# COMPUTE_CLUSTER0_CTL_CFG register map
Vendor: Texas Instruments
Registers are 32-bit, read-write, reset 0x0 unless marked. A register's access mark holds for its fields unless they carry their own. Offsets are as the file gives them; [hi:lo] are bit positions; {n}, {i} and the like mark numbered series.

## COMPUTE_CLUSTER0_CTL_CFG (part 2 of 3)
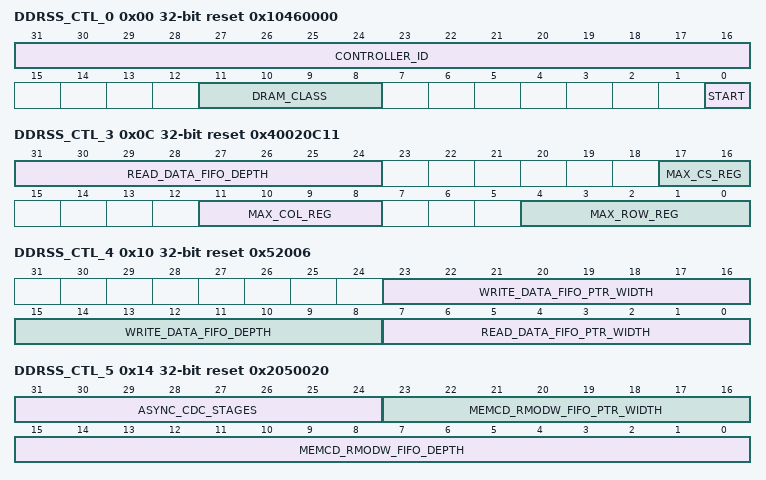
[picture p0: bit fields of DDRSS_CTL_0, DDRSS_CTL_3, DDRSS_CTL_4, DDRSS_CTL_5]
0x00 DDRSS_CTL_0 access per field reset 0x10460000
  [31:16] CONTROLLER_ID ro — Holds the controller product id number.
  [11:8] DRAM_CLASS rw — Defines the class of DRAM memory which is connected to the controller.7h - LPDDR3Bh - LPDDR4All other values reserved
  [0] START rw — Initiate command processing in the controller.
0x04 DDRSS_CTL_1 ro reset 0x67433A40
  [31:0] CONTROLLER_VERSION_0 — Holds the controller version id.
0x08 DDRSS_CTL_2 ro reset 0x22117A20
  [31:0] CONTROLLER_VERSION_1 — Holds the controller version id.
0x0C DDRSS_CTL_3 ro reset 0x40020C11
  [31:24] READ_DATA_FIFO_DEPTH — Reports the depth of the controller core read data queue.
  [17:16] MAX_CS_REG — Holds the maximum number of chip selects available.
  [11:8] MAX_COL_REG — Holds the maximum width of column address in DRAMs.
  [4:0] MAX_ROW_REG — Holds the maximum width of memory address bus.
0x10 DDRSS_CTL_4 ro reset 0x52006
  [23:16] WRITE_DATA_FIFO_PTR_WIDTH — Reports the width of the controller core write data latency queue pointer.
  [15:8] WRITE_DATA_FIFO_DEPTH — Reports the depth of the controller core write data latency queue.
  [7:0] READ_DATA_FIFO_PTR_WIDTH — Reports the width of the controller core read data queue pointer.
0x14 DDRSS_CTL_5 ro reset 0x2050020
  [31:24] ASYNC_CDC_STAGES — Reports the number of synchronizer delays specified for the asynchronous boundary crossings.
  [23:16] MEMCD_RMODW_FIFO_PTR_WIDTH — Reports the width of the controller core read/modify/write FIFO pointer.
  [15:0] MEMCD_RMODW_FIFO_DEPTH — Reports the depth of the controller core read/modify/write FIFO.
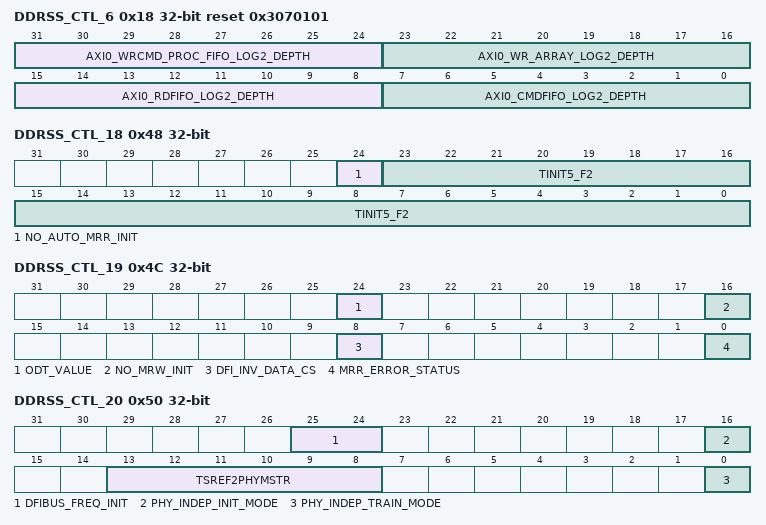
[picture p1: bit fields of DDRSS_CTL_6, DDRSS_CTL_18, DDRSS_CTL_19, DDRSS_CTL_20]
0x18 DDRSS_CTL_6 ro reset 0x3070101
  [31:24] AXI0_WRCMD_PROC_FIFO_LOG2_DEPTH — Reports the depth of the AXI port 0 write command processing FIFO.
  [23:16] AXI0_WR_ARRAY_LOG2_DEPTH — Reports the depth of the AXI port 0 write data array.
  [15:8] AXI0_RDFIFO_LOG2_DEPTH — Reports the depth of the AXI port 0 read data FIFO.
  [7:0] AXI0_CMDFIFO_LOG2_DEPTH — Reports the depth of the AXI port 0 command FIFO.
0x1C DDRSS_CTL_7
  [23:0] TINIT_F0 — DRAM TINIT value for frequency copy 0 in cycles.
{0x0+4i} DDRSS_CTL_{i} (i=8..10)
  [23:0] TINIT{i-5}_F0 — DRAM TINIT{i-5} value for frequency copy 0 in cycles.
0x2C DDRSS_CTL_11
  [23:0] TINIT_F1 — DRAM TINIT value for frequency copy 1 in cycles.
{0x0+4i} DDRSS_CTL_{i} (i=12..14)
  [23:0] TINIT{i-9}_F1 — DRAM TINIT{i-9} value for frequency copy 1 in cycles.
0x3C DDRSS_CTL_15
  [23:0] TINIT_F2 — DRAM TINIT value for frequency copy 2 in cycles.
0x40 DDRSS_CTL_16
  [23:0] TINIT3_F2 — DRAM TINIT3 value for frequency copy 2 in cycles.
0x44 DDRSS_CTL_17
  [23:0] TINIT4_F2 — DRAM TINIT4 value for frequency copy 2 in cycles.
0x48 DDRSS_CTL_18
  [24] NO_AUTO_MRR_INIT — Disable MRR commands during initialization.
  [23:0] TINIT5_F2 — DRAM TINIT5 value for frequency copy 2 in cycles.
0x4C DDRSS_CTL_19 access per field
  [24] ODT_VALUE rw — When using LPDDR4, this value will be driven out on the dfi_odt signal.
  [16] NO_MRW_INIT rw — Disable MRW commands during initialization.
  [8] DFI_INV_DATA_CS rw — Forces the inversion of the dfi_rddata_cs_n_X and dfi_wrdata_cs_n_X signals.
  [0] MRR_ERROR_STATUS ro — Indicates that an MRR was issued while in self-refresh.
0x50 DDRSS_CTL_20
  [25:24] DFIBUS_FREQ_INIT — Defines the initial DFI bus frequency.
  [16] PHY_INDEP_INIT_MODE — Enable PHY independent initailization mode commands during initialization.
  [13:8] TSREF2PHYMSTR — Specifies the minimum time after a self-refresh exit command on the DFI bus that the Controller will wait for the PHY to assert the dfi_phymstr_req signal, before completing other commands.
  [0] PHY_INDEP_TRAIN_MODE — Enable PHY independent training mode commands during initialization.
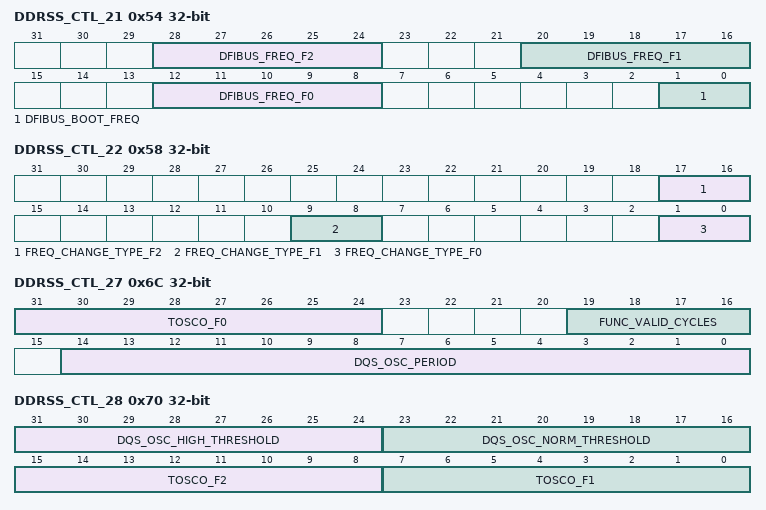
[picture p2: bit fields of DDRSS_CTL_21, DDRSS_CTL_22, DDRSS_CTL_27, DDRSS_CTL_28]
0x54 DDRSS_CTL_21
  [28:24] DFIBUS_FREQ_F2 — Defines the DFI bus frequency for frequency copy 2.
  [20:16] DFIBUS_FREQ_F1 — Defines the DFI bus frequency for frequency copy 1.
  [12:8] DFIBUS_FREQ_F0 — Defines the DFI bus frequency for frequency copy 0.
  [1:0] DFIBUS_BOOT_FREQ — Defines the DFI bus boot frequency.
0x58 DDRSS_CTL_22
  [17:16] FREQ_CHANGE_TYPE_F2 — Defines the encoded frequency driven out on the cntrl_freq_change_req_type signal during a frequency change operation.
  [9:8] FREQ_CHANGE_TYPE_F1 — Defines the encoded frequency driven out on the cntrl_freq_change_req_type signal during a frequency change operation.
  [1:0] FREQ_CHANGE_TYPE_F0 — Defines the encoded frequency driven out on the cntrl_freq_change_req_type signal during a frequency change operation.
0x5C DDRSS_CTL_23
  [31:0] TRST_PWRON — Duration of memory reset during power-on initialization.
0x60 DDRSS_CTL_24
  [31:0] CKE_INACTIVE — Number of cycles after reset before CKE will be active.
0x68 DDRSS_CTL_26
  [16] DQS_OSC_ENABLE — Enable DQS oscillator measurement function in DRAM.
0x6C DDRSS_CTL_27
  [31:24] TOSCO_F0 — Number of cycles for tOSCO timing parameter for frequency copy 0.
  [19:16] FUNC_VALID_CYCLES — Number of cycles to hold dfi_function_valid asserted.
  [14:0] DQS_OSC_PERIOD — Number of cycles to run the oscillator measurement.
0x70 DDRSS_CTL_28
  [31:24] DQS_OSC_HIGH_THRESHOLD — Number of long counts until the high priority request is asserted for DQS Oscillator.
  [23:16] DQS_OSC_NORM_THRESHOLD — Number of long counts until the normal priority request is asserted for DQS Oscillator.
  [15:8] TOSCO_F2 — Number of cycles for tOSCO timing parameter for frequency copy 2.
  [7:0] TOSCO_F1 — Number of cycles for tOSCO timing parameter for frequency copy 1.
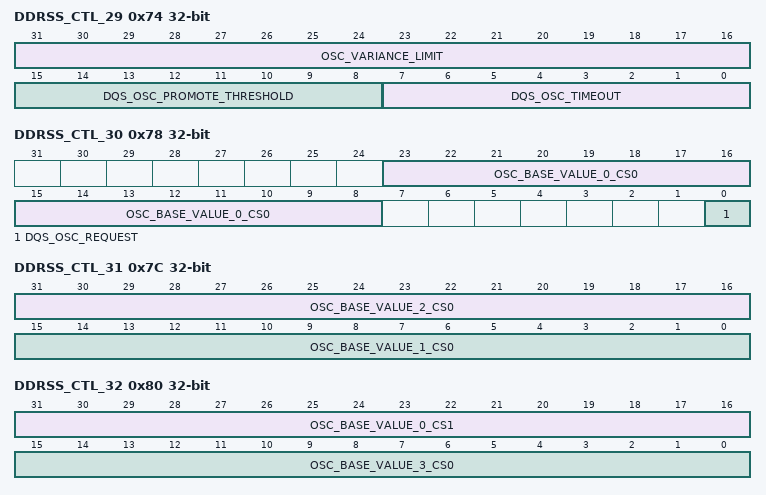
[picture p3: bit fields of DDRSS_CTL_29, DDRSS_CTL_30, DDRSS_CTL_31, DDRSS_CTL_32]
0x74 DDRSS_CTL_29
  [31:16] OSC_VARIANCE_LIMIT — Allowed difference between base value and DQS Oscillator measurement.
  [15:8] DQS_OSC_PROMOTE_THRESHOLD — Number of long counts until a software request for the DQS Oscillator is promoted to high priority.
  [7:0] DQS_OSC_TIMEOUT — Number of long counts until the timeout is asserted for DQS Oscillator.
0x78 DDRSS_CTL_30 access per field
  [23:8] OSC_BASE_VALUE_0_CS0 ro — Base value for device 0 on chip 0.
  [0] DQS_OSC_REQUEST wo — Software request for DQS Oscillator measurement function in DRAM.
0x7C DDRSS_CTL_31 ro
  [31:16] OSC_BASE_VALUE_2_CS0 — Base value for device 2 on chip 0.
  [15:0] OSC_BASE_VALUE_1_CS0 — Base value for device 1 on chip 0.
0x80 DDRSS_CTL_32 ro
  [31:16] OSC_BASE_VALUE_0_CS1 — Base value for device 0 on chip 1.
  [15:0] OSC_BASE_VALUE_3_CS0 — Base value for device 3 on chip 0.
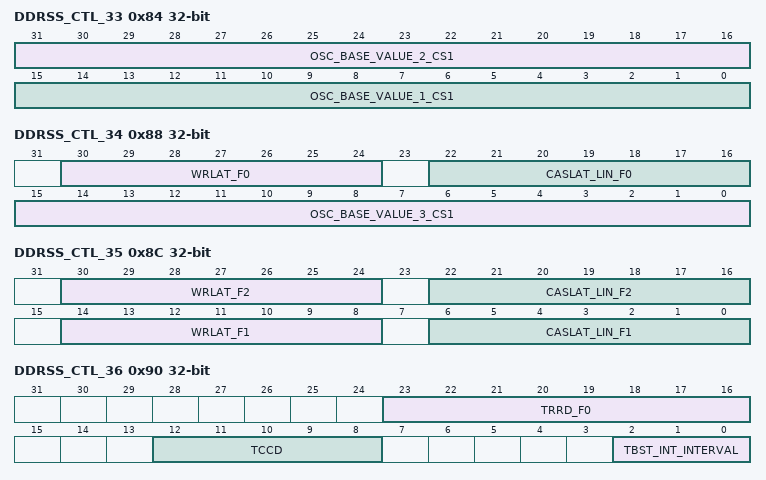
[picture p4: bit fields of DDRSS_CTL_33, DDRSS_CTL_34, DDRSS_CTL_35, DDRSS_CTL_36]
0x84 DDRSS_CTL_33 ro
  [31:16] OSC_BASE_VALUE_2_CS1 — Base value for device 2 on chip 1.
  [15:0] OSC_BASE_VALUE_1_CS1 — Base value for device 1 on chip 1.
0x88 DDRSS_CTL_34 access per field
  [30:24] WRLAT_F0 rw — DRAM WRLAT value for frequency copy 0 in cycles.
  [22:16] CASLAT_LIN_F0 rw — Sets latency from read command send to data receive from/to controller for frequency copy 0.
  [15:0] OSC_BASE_VALUE_3_CS1 ro — Base value for device 3 on chip 1.
0x8C DDRSS_CTL_35
  [30:24] WRLAT_F2 — DRAM WRLAT value for frequency copy 2 in cycles.
  [22:16] CASLAT_LIN_F2 — Sets latency from read command send to data receive from/to controller for frequency copy 2.
  [14:8] WRLAT_F1 — DRAM WRLAT value for frequency copy 1 in cycles.
  [6:0] CASLAT_LIN_F1 — Sets latency from read command send to data receive from/to controller for frequency copy 1.
0x90 DDRSS_CTL_36
  [23:16] TRRD_F0 — DRAM TRRD value for frequency copy 0 in cycles.
  [12:8] TCCD — DRAM CAS-to-CAS value in cycles.
  [2:0] TBST_INT_INTERVAL — DRAM burst interrupt interval value in cycles.
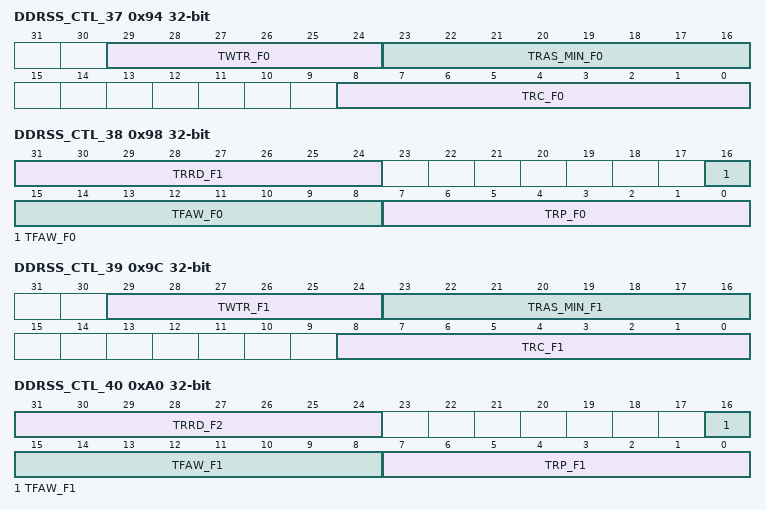
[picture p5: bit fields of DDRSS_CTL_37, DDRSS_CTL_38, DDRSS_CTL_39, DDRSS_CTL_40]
0x94 DDRSS_CTL_37
  [29:24] TWTR_F0 — DRAM TWTR value for frequency copy 0 in cycles.
  [23:16] TRAS_MIN_F0 — DRAM TRAS_MIN value for frequency copy 0 in cycles.
  [8:0] TRC_F0 — DRAM TRC value for frequency copy 0 in cycles.
0x98 DDRSS_CTL_38
  [31:24] TRRD_F1 — DRAM TRRD value for frequency copy 1 in cycles.
  [16:8] TFAW_F0 — DRAM TFAW value for frequency copy 0 in cycles.
  [7:0] TRP_F0 — DRAM TRP value for frequency copy 0 in cycles.
0x9C DDRSS_CTL_39
  [29:24] TWTR_F1 — DRAM TWTR value for frequency copy 1 in cycles.
  [23:16] TRAS_MIN_F1 — DRAM TRAS_MIN value for frequency copy 1 in cycles.
  [8:0] TRC_F1 — DRAM TRC value for frequency copy 1 in cycles.
0xA0 DDRSS_CTL_40
  [31:24] TRRD_F2 — DRAM TRRD value for frequency copy 2 in cycles.
  [16:8] TFAW_F1 — DRAM TFAW value for frequency copy 1 in cycles.
  [7:0] TRP_F1 — DRAM TRP value for frequency copy 1 in cycles.
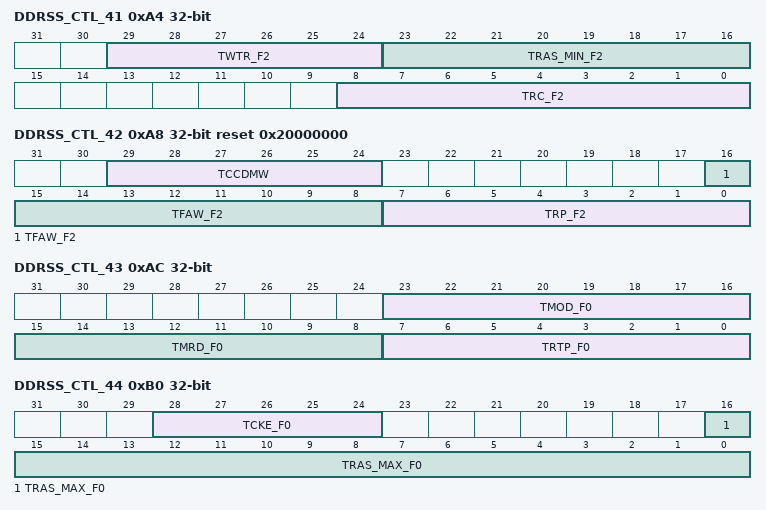
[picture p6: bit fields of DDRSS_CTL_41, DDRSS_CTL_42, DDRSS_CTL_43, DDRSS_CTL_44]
0xA4 DDRSS_CTL_41
  [29:24] TWTR_F2 — DRAM TWTR value for frequency copy 2 in cycles.
  [23:16] TRAS_MIN_F2 — DRAM TRAS_MIN value for frequency copy 2 in cycles.
  [8:0] TRC_F2 — DRAM TRC value for frequency copy 2 in cycles.
0xA8 DDRSS_CTL_42 reset 0x20000000
  [29:24] TCCDMW — DRAM CAS-to-CAS masked write value in cycles.
  [16:8] TFAW_F2 — DRAM TFAW value for frequency copy 2 in cycles.
  [7:0] TRP_F2 — DRAM TRP value for frequency copy 2 in cycles.
0xAC DDRSS_CTL_43
  [23:16] TMOD_F0 — DRAM TMOD value for frequency copy 0 in cycles.
  [15:8] TMRD_F0 — DRAM TMRD value for frequency copy 0 in cycles.
  [7:0] TRTP_F0 — DRAM TRTP value for frequency copy 0 in cycles.
0xB0 DDRSS_CTL_44
  [28:24] TCKE_F0 — Minimum CKE pulse width for frequency copy 0.
  [16:0] TRAS_MAX_F0 — DRAM TRAS_MAX value for frequency copy 0 in cycles.
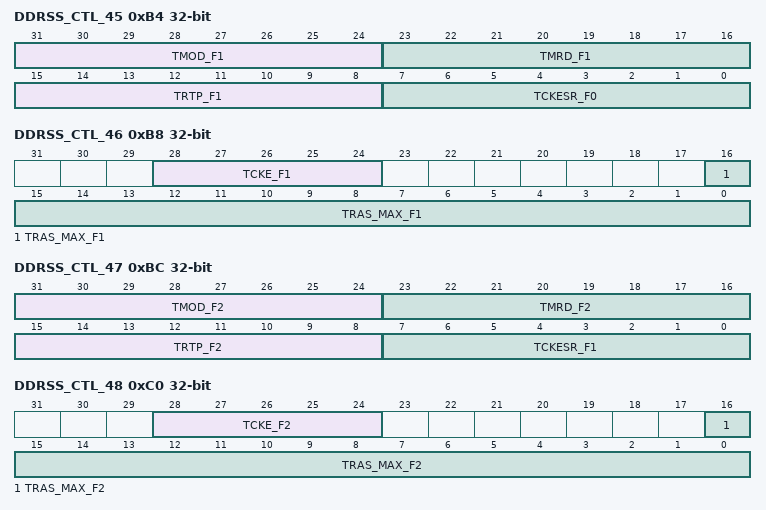
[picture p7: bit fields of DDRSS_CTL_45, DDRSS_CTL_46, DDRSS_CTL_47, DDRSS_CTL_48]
0xB4 DDRSS_CTL_45
  [31:24] TMOD_F1 — DRAM TMOD value for frequency copy 1 in cycles.
  [23:16] TMRD_F1 — DRAM TMRD value for frequency copy 1 in cycles.
  [15:8] TRTP_F1 — DRAM TRTP value for frequency copy 1 in cycles.
  [7:0] TCKESR_F0 — Minimum CKE low pulse width during a self-refresh for frequency copy 0.
0xB8 DDRSS_CTL_46
  [28:24] TCKE_F1 — Minimum CKE pulse width for frequency copy 1.
  [16:0] TRAS_MAX_F1 — DRAM TRAS_MAX value for frequency copy 1 in cycles.
0xBC DDRSS_CTL_47
  [31:24] TMOD_F2 — DRAM TMOD value for frequency copy 2 in cycles.
  [23:16] TMRD_F2 — DRAM TMRD value for frequency copy 2 in cycles.
  [15:8] TRTP_F2 — DRAM TRTP value for frequency copy 2 in cycles.
  [7:0] TCKESR_F1 — Minimum CKE low pulse width during a self-refresh for frequency copy 1.
0xC0 DDRSS_CTL_48
  [28:24] TCKE_F2 — Minimum CKE pulse width for frequency copy 2.
  [16:0] TRAS_MAX_F2 — DRAM TRAS_MAX value for frequency copy 2 in cycles.
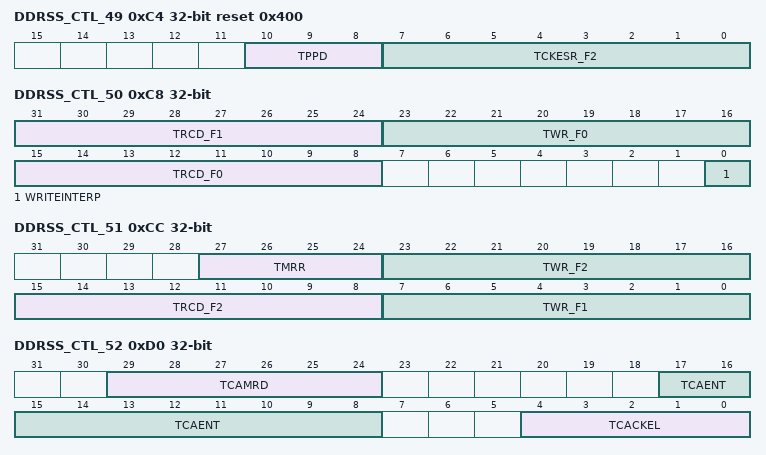
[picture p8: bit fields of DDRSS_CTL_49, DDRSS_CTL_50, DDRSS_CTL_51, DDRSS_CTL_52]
0xC4 DDRSS_CTL_49 reset 0x400
  [10:8] TPPD — DRAM TPPD value in cycles.
  [7:0] TCKESR_F2 — Minimum CKE low pulse width during a self-refresh for frequency copy 2.
0xC8 DDRSS_CTL_50
  [31:24] TRCD_F1 — DRAM TRCD value for frequency copy 1 in cycles.
  [23:16] TWR_F0 — DRAM TWR value for frequency copy 0 in cycles.
  [15:8] TRCD_F0 — DRAM TRCD value for frequency copy 0 in cycles.
  [0] WRITEINTERP — Allow controller to interrupt a write burst to the DRAMs with a read command.
0xCC DDRSS_CTL_51
  [27:24] TMRR — DRAM TMRR value in cycles.
  [23:16] TWR_F2 — DRAM TWR value for frequency copy 2 in cycles.
  [15:8] TRCD_F2 — DRAM TRCD value for frequency copy 2 in cycles.
  [7:0] TWR_F1 — DRAM TWR value for frequency copy 1 in cycles.
0xD0 DDRSS_CTL_52
  [29:24] TCAMRD — DRAM TCAMRD value in cycles.
  [17:8] TCAENT — DRAM TCAENT value in cycles.
  [4:0] TCACKEL — DRAM TCACKEL value in cycles.
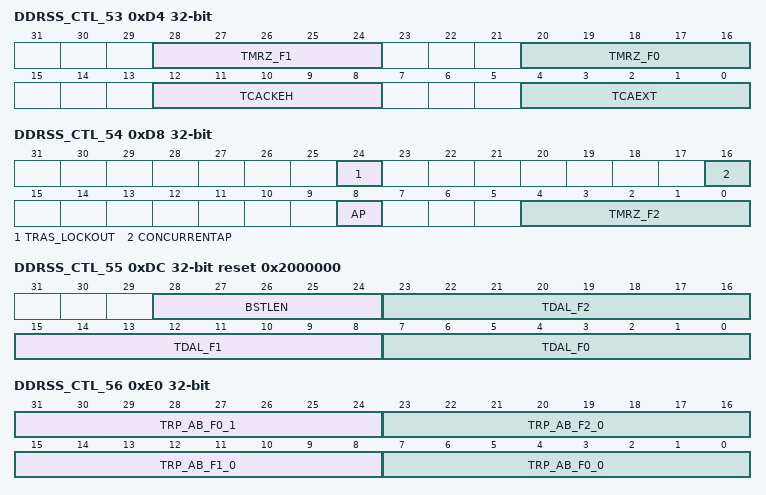
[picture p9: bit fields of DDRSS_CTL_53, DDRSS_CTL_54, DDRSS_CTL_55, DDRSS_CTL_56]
0xD4 DDRSS_CTL_53
  [28:24] TMRZ_F1 — DRAM TMRZ value for frequency copy 1 in cycles.
  [20:16] TMRZ_F0 — DRAM TMRZ value for frequency copy 0 in cycles.
  [12:8] TCACKEH — DRAM TCACKEH value in cycles.
  [4:0] TCAEXT — DRAM TCAEXT value in cycles.
0xD8 DDRSS_CTL_54
  [24] TRAS_LOCKOUT — IF the DRAM supports it, this allows the controller to execute auto pre-charge commands before the TRAS_MIN parameter expires.
  [16] CONCURRENTAP — IF the DRAM supports it, this allows the controller to issue commands to other banks while a bank is in auto pre-charge.
  [8] AP — Enable auto pre-charge mode of controller.
  [4:0] TMRZ_F2 — DRAM TMRZ value for frequency copy 2 in cycles.
0xDC DDRSS_CTL_55 reset 0x2000000
  [28:24] BSTLEN — Encoded burst length sent to DRAMs during initialization.
  [23:16] TDAL_F2 — DRAM TDAL value for frequency copy 2 in cycles.
  [15:8] TDAL_F1 — DRAM TDAL value for frequency copy 1 in cycles.
  [7:0] TDAL_F0 — DRAM TDAL value for frequency copy 0 in cycles.
0xE0 DDRSS_CTL_56
  [31:24] TRP_AB_F0_1 — DRAM TRP all bank value for frequency copy 0 in cycles for chip select 1.
  [23:16] TRP_AB_F2_0 — DRAM TRP all bank value for frequency copy 2 in cycles for chip select 0.
  [15:8] TRP_AB_F1_0 — DRAM TRP all bank value for frequency copy 1 in cycles for chip select 0.
  [7:0] TRP_AB_F0_0 — DRAM TRP all bank value for frequency copy 0 in cycles for chip select 0.
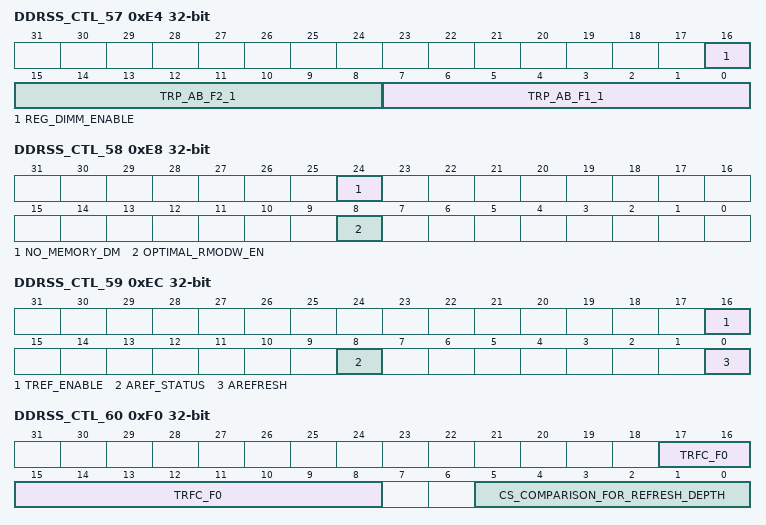
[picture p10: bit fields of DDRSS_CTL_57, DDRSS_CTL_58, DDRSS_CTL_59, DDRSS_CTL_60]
0xE4 DDRSS_CTL_57
  [16] REG_DIMM_ENABLE — Enable registered DIMM operation of the controller.
  [15:8] TRP_AB_F2_1 — DRAM TRP all bank value for frequency copy 2 in cycles for chip select 1.
  [7:0] TRP_AB_F1_1 — DRAM TRP all bank value for frequency copy 1 in cycles for chip select 1.
0xE8 DDRSS_CTL_58
  [24] NO_MEMORY_DM — Indicates that the external DRAM does not support DM masking.
  [8] OPTIMAL_RMODW_EN — Enables optimized RMODW logic in the controller.
0xEC DDRSS_CTL_59 access per field
  [16] TREF_ENABLE rw — Issue auto-refresh commands to the DRAMs at the interval defined in the TREF parameter.
  [8] AREF_STATUS ro — Indicates a SR error associated with the AREF interrupt.
  [0] AREFRESH wo — Initiate auto-refresh at the end of the current burst boundary.
0xF0 DDRSS_CTL_60
  [17:8] TRFC_F0 — DRAM TRFC value for frequency copy 0 in cycles.
  [5:0] CS_COMPARISON_FOR_REFRESH_DEPTH — Defines the number of entries of the command queue that the refresh logic will consider for sending a refresh command.
0xF4 DDRSS_CTL_61
  [19:0] TREF_F0 — DRAM TREF value for frequency copy 0 in cycles.
0xF8 DDRSS_CTL_62
  [9:0] TRFC_F1 — DRAM TRFC value for frequency copy 1 in cycles.
0xFC DDRSS_CTL_63
  [19:0] TREF_F1 — DRAM TREF value for frequency copy 1 in cycles.
0x100 DDRSS_CTL_64
  [9:0] TRFC_F2 — DRAM TRFC value for frequency copy 2 in cycles.
0x104 DDRSS_CTL_65
  [19:0] TREF_F2 — DRAM TREF value for frequency copy 2 in cycles.
0x108 DDRSS_CTL_66
  [19:0] TREF_INTERVAL — Defines the cycles between refreshes to different chip selects.
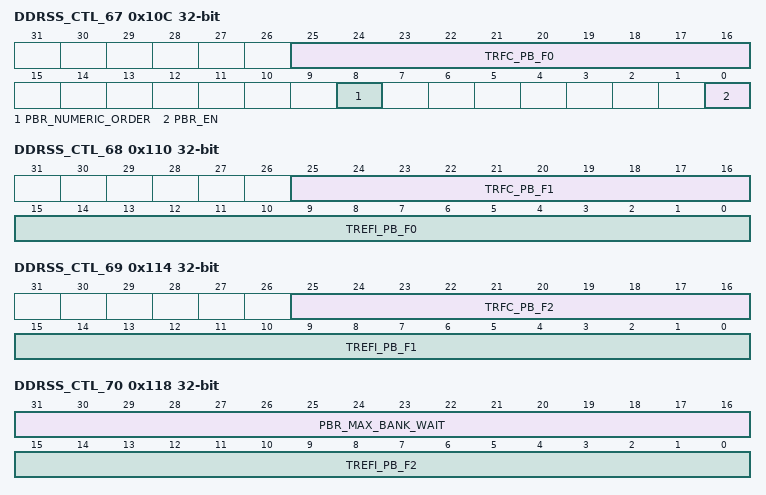
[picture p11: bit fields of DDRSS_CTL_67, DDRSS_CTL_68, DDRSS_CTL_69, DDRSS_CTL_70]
0x10C DDRSS_CTL_67
  [25:16] TRFC_PB_F0 — DRAM TRFC_PB value for frequency copy 0 in cycles.
  [8] PBR_NUMERIC_ORDER — Enables the PBR to run REFpb commands in numeric bank order (0,1,2,3, etc.) When disabled, the order may be modified if supported by the memory type.
  [0] PBR_EN — Enables the per-bank refresh feature.
0x110 DDRSS_CTL_68
  [25:16] TRFC_PB_F1 — DRAM TRFC_PB value for frequency copy 1 in cycles.
  [15:0] TREFI_PB_F0 — DRAM TREFI_PB value for frequency copy 0 in cycles.
0x114 DDRSS_CTL_69
  [25:16] TRFC_PB_F2 — DRAM TRFC_PB value for frequency copy 2 in cycles.
  [15:0] TREFI_PB_F1 — DRAM TREFI_PB value for frequency copy 1 in cycles.
0x118 DDRSS_CTL_70
  [31:16] PBR_MAX_BANK_WAIT — Defines the maximum number of cycles that the PBR module will wait for Strategy to release the target bank until the PBR will assert the inhibit and close the target bank.
  [15:0] TREFI_PB_F2 — DRAM TREFI_PB value for frequency copy 2 in cycles.
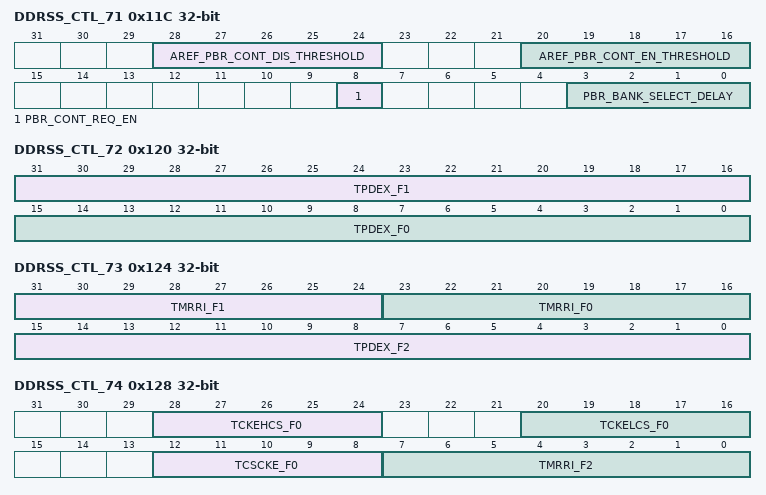
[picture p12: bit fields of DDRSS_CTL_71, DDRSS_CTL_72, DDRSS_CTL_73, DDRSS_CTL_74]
0x11C DDRSS_CTL_71
  [28:24] AREF_PBR_CONT_DIS_THRESHOLD — Sets the auto-refresh request count threshold when the PBR continuous refresh request enable will be deasserted.
  [20:16] AREF_PBR_CONT_EN_THRESHOLD — Sets the auto-refresh request count threshold when the PBR continuous refresh request enable will be asserted.
  [8] PBR_CONT_REQ_EN — Enables the per-bank refresh continuous request feature.
  [3:0] PBR_BANK_SELECT_DELAY — Defines the PBR bank select to command delay, the time from bank selection to when the command queue bank selection logic is guaranteed to have blocked the bank.
0x120 DDRSS_CTL_72
  [31:16] TPDEX_F1 — DRAM TPDEX value for frequency copy 1 in cycles.
  [15:0] TPDEX_F0 — DRAM TPDEX value for frequency copy 0 in cycles.
0x124 DDRSS_CTL_73
  [31:24] TMRRI_F1 — DRAM TMRRI value for frequency copy 1 in cycles.
  [23:16] TMRRI_F0 — DRAM TMRRI value for frequency copy 0 in cycles.
  [15:0] TPDEX_F2 — DRAM TPDEX value for frequency copy 2 in cycles.
0x128 DDRSS_CTL_74
  [28:24] TCKEHCS_F0 — DRAM TCKEHCS value for frequency copy 0 in cycles.
  [20:16] TCKELCS_F0 — DRAM TCKELCS value for frequency copy 0 in cycles.
  [12:8] TCSCKE_F0 — DRAM TCSCKE value for frequency copy 0 in cycles.
  [7:0] TMRRI_F2 — DRAM TMRRI value for frequency copy 2 in cycles.
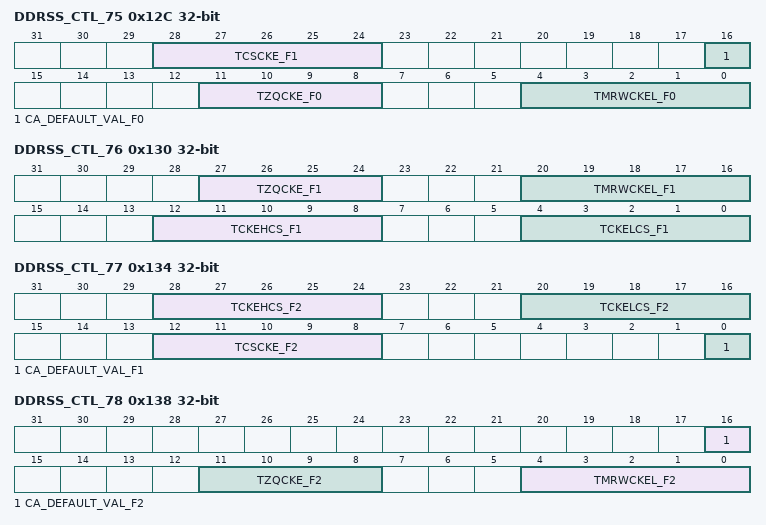
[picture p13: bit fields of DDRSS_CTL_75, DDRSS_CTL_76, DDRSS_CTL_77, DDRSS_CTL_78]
0x12C DDRSS_CTL_75
  [28:24] TCSCKE_F1 — DRAM TCSCKE value for frequency copy 1 in cycles.
  [16] CA_DEFAULT_VAL_F0 — Defines how unused address/command bits are driven for frequency copy 0.
  [11:8] TZQCKE_F0 — DRAM TZQCKE value for frequency copy 0 in cycles.
  [4:0] TMRWCKEL_F0 — DRAM TMRWCKEL value for frequency copy 0 in cycles.
0x130 DDRSS_CTL_76
  [27:24] TZQCKE_F1 — DRAM TZQCKE value for frequency copy 1 in cycles.
  [20:16] TMRWCKEL_F1 — DRAM TMRWCKEL value for frequency copy 1 in cycles.
  [12:8] TCKEHCS_F1 — DRAM TCKEHCS value for frequency copy 1 in cycles.
  [4:0] TCKELCS_F1 — DRAM TCKELCS value for frequency copy 1 in cycles.
0x134 DDRSS_CTL_77
  [28:24] TCKEHCS_F2 — DRAM TCKEHCS value for frequency copy 2 in cycles.
  [20:16] TCKELCS_F2 — DRAM TCKELCS value for frequency copy 2 in cycles.
  [12:8] TCSCKE_F2 — DRAM TCSCKE value for frequency copy 2 in cycles.
  [0] CA_DEFAULT_VAL_F1 — Defines how unused address/command bits are driven for frequency copy 1.
0x138 DDRSS_CTL_78
  [16] CA_DEFAULT_VAL_F2 — Defines how unused address/command bits are driven for frequency copy 2.
  [11:8] TZQCKE_F2 — DRAM TZQCKE value for frequency copy 2 in cycles.
  [4:0] TMRWCKEL_F2 — DRAM TMRWCKEL value for frequency copy 2 in cycles.
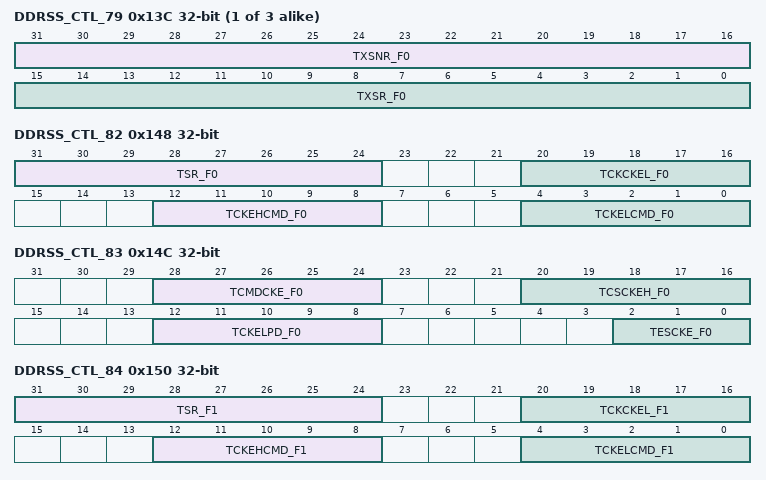
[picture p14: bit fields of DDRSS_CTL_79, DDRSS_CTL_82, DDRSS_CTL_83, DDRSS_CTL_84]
{0x0+4i} DDRSS_CTL_{i} (i=79..81)
  [31:16] TXSNR_F{i-79} — DRAM TXSNR value for frequency copy {i-79} in cycles.
  [15:0] TXSR_F{i-79} — DRAM TXSR value for frequency copy {i-79} in cycles.
0x148 DDRSS_CTL_82
  [31:24] TSR_F0 — DRAM TSR value for frequency copy 0 in cycles.
  [20:16] TCKCKEL_F0 — DRAM TCKCKEL value for frequency copy 0 in cycles.
  [12:8] TCKEHCMD_F0 — DRAM TCKEHCMD value for frequency copy 0 in cycles.
  [4:0] TCKELCMD_F0 — DRAM TCKELCMD value for frequency copy 0 in cycles.
0x14C DDRSS_CTL_83
  [28:24] TCMDCKE_F0 — DRAM TCMDCKE value for frequency copy 0 in cycles.
  [20:16] TCSCKEH_F0 — DRAM TCSCKEH value for frequency copy 0 in cycles.
  [12:8] TCKELPD_F0 — DRAM TCKELPD value for frequency copy 0 in cycles.
  [2:0] TESCKE_F0 — DRAM TESCKE value for frequency copy 0 in cycles.
0x150 DDRSS_CTL_84
  [31:24] TSR_F1 — DRAM TSR value for frequency copy 1 in cycles.
  [20:16] TCKCKEL_F1 — DRAM TCKCKEL value for frequency copy 1 in cycles.
  [12:8] TCKEHCMD_F1 — DRAM TCKEHCMD value for frequency copy 1 in cycles.
  [4:0] TCKELCMD_F1 — DRAM TCKELCMD value for frequency copy 1 in cycles.
0x154 DDRSS_CTL_85
  [28:24] TCMDCKE_F1 — DRAM TCMDCKE value for frequency copy 1 in cycles.
  [20:16] TCSCKEH_F1 — DRAM TCSCKEH value for frequency copy 1 in cycles.
  [12:8] TCKELPD_F1 — DRAM TCKELPD value for frequency copy 1 in cycles.
  [2:0] TESCKE_F1 — DRAM TESCKE value for frequency copy 1 in cycles.
0x158 DDRSS_CTL_86
  [31:24] TSR_F2 — DRAM TSR value for frequency copy 2 in cycles.
  [20:16] TCKCKEL_F2 — DRAM TCKCKEL value for frequency copy 2 in cycles.
  [12:8] TCKEHCMD_F2 — DRAM TCKEHCMD value for frequency copy 2 in cycles.
  [4:0] TCKELCMD_F2 — DRAM TCKELCMD value for frequency copy 2 in cycles.
0x15C DDRSS_CTL_87
  [28:24] TCMDCKE_F2 — DRAM TCMDCKE value for frequency copy 2 in cycles.
  [20:16] TCSCKEH_F2 — DRAM TCSCKEH value for frequency copy 2 in cycles.
  [12:8] TCKELPD_F2 — DRAM TCKELPD value for frequency copy 2 in cycles.
  [2:0] TESCKE_F2 — DRAM TESCKE value for frequency copy 2 in cycles.
0x160 DDRSS_CTL_88
  [26:24] CKE_DELAY — Additional cycles to delay CKE for status reporting.
  [16] ENABLE_QUICK_SREFRESH — Allow user to interrupt memory initialization to enter self-refresh mode.
  [0] PWRUP_SREFRESH_EXIT — Allow powerup via self-refresh instead of full memory initialization.
0x164 DDRSS_CTL_89 access per field
  [24] DFS_CALVL_EN rw — Enables CA training during a DFS exit.
  [16] DFS_ZQ_EN rw — Enables ZQ calibration during a DFS exit.
  [9:8] DFS_STATUS ro — Holds the error associated with the DFS interrupt.
0x168 DDRSS_CTL_90
  [16] DFS_RDLVL_GATE_EN — Enables read gate training during a DFS exit.
  [8] DFS_RDLVL_EN — Enables read data eye training during a DFS exit.
  [0] DFS_WRLVL_EN — Enables write leveling during a DFS exit.
0x16C DDRSS_CTL_91
  [31:16] DFS_PROMOTE_THRESHOLD_F1 — DFS promotion number of long counts until the high priority request is asserted for frequency copy 1.
  [15:0] DFS_PROMOTE_THRESHOLD_F0 — DFS promotion number of long counts until the high priority request is asserted for frequency copy 0.
0x170 DDRSS_CTL_92 access per field
  [18:16] ZQ_STATUS_LOG ro — Indicates what kind of ZQ command was terminated without execution that caused the ZQ status interrupt to assert.
  [15:0] DFS_PROMOTE_THRESHOLD_F2 rw — DFS promotion number of long counts until the high priority request is asserted for frequency copy 2.
0x178 DDRSS_CTL_94
  [31:16] UPD_CTRLUPD_HIGH_THRESHOLD_F0 — DFI control update number of long counts until the high priority request is asserted for frequency copy 0.
  [15:0] UPD_CTRLUPD_NORM_THRESHOLD_F0 — DFI control update number of long counts until the normal priority request is asserted for frequency copy 0.
0x17C DDRSS_CTL_95
  [31:16] UPD_CTRLUPD_SW_PROMOTE_THRESHOLD_F0 — DFI control update SW promotion number of long counts until the high priority request is asserted for frequency copy 0.
  [15:0] UPD_CTRLUPD_TIMEOUT_F0 — DFI control update number of long counts until the timeout is asserted for frequency copy 0.
0x180 DDRSS_CTL_96
  [31:16] UPD_CTRLUPD_NORM_THRESHOLD_F1 — DFI control update number of long counts until the normal priority request is asserted for frequency copy 1.
  [15:0] UPD_PHYUPD_DFI_PROMOTE_THRESHOLD_F0 — DFI PHY update DFI promotion number of long counts until the high priority request is asserted for frequency copy 0.
0x184 DDRSS_CTL_97
  [31:16] UPD_CTRLUPD_TIMEOUT_F1 — DFI control update number of long counts until the timeout is asserted for frequency copy 1.
  [15:0] UPD_CTRLUPD_HIGH_THRESHOLD_F1 — DFI control update number of long counts until the high priority request is asserted for frequency copy 1.
0x188 DDRSS_CTL_98
  [31:16] UPD_PHYUPD_DFI_PROMOTE_THRESHOLD_F1 — DFI PHY update DFI promotion number of long counts until the high priority request is asserted for frequency copy 1.
  [15:0] UPD_CTRLUPD_SW_PROMOTE_THRESHOLD_F1 — DFI control update SW promotion number of long counts until the high priority request is asserted for frequency copy 1.
0x18C DDRSS_CTL_99
  [31:16] UPD_CTRLUPD_HIGH_THRESHOLD_F2 — DFI control update number of long counts until the high priority request is asserted for frequency copy 2.
  [15:0] UPD_CTRLUPD_NORM_THRESHOLD_F2 — DFI control update number of long counts until the normal priority request is asserted for frequency copy 2.
0x190 DDRSS_CTL_100
  [31:16] UPD_CTRLUPD_SW_PROMOTE_THRESHOLD_F2 — DFI control update SW promotion number of long counts until the high priority request is asserted for frequency copy 2.
  [15:0] UPD_CTRLUPD_TIMEOUT_F2 — DFI control update number of long counts until the timeout is asserted for frequency copy 2.
0x194 DDRSS_CTL_101
  [15:0] UPD_PHYUPD_DFI_PROMOTE_THRESHOLD_F2 — DFI PHY update DFI promotion number of long counts until the high priority request is asserted for frequency copy 2.
0x198 DDRSS_CTL_102
  [31:0] TDFI_PHYMSTR_MAX_F0 — Defines the DFI tPHYMSTR_MAX timing parameter (in DFI clocks), the maximum cycles that dfi_phymstr_req can be asserted following the assertion of dfi_phymstr_ack, for frequency copy 0.
{0x0+4i} DDRSS_CTL_{i} (i=103..106)
  [31:0] TDFI_PHYMSTR_MAX_TYPE{i-103}_F0 — Defines the DFI 4.0v2 tPHYMSTR_MAX_TYPE{i-103} timing parameter (in DFI clocks), the maximum cycles that dfi_phymstr_req can be asserted following the assertion of dfi_phymstr_ack for dfi_phymstr_type={i-103}, for frequency copy 0.
0x1AC DDRSS_CTL_107
  [15:0] PHYMSTR_DFI4_PROMOTE_THRESHOLD_F0 — Defines the DFI(4.0 and 4.0v2) PHY master request promotion number of regular (not long) counts until the high priority request is asserted for frequency copy 0.
0x1B0 DDRSS_CTL_108
  [19:0] TDFI_PHYMSTR_RESP_F0 — Defines the DFI tPHYMSTR_RESP timing parameter (in DFI clocks), the maximum cycles between a dfi_phymstr_req assertion and a dfi_phymstr_ack assertion, for frequency copy 0.
0x1B4 DDRSS_CTL_109
  [31:0] TDFI_PHYMSTR_MAX_F1 — Defines the DFI tPHYMSTR_MAX timing parameter (in DFI clocks), the maximum cycles that dfi_phymstr_req can be asserted following the assertion of dfi_phymstr_ack, for frequency copy 1.
{0x0+4i} DDRSS_CTL_{i} (i=110..113)
  [31:0] TDFI_PHYMSTR_MAX_TYPE{i-110}_F1 — Defines the DFI 4.0v2 tPHYMSTR_MAX_TYPE{i-110} timing parameter (in DFI clocks), the maximum cycles that dfi_phymstr_req can be asserted following the assertion of dfi_phymstr_ack for dfi_phymstr_type={i-110}, for frequency copy 1.
0x1C8 DDRSS_CTL_114
  [15:0] PHYMSTR_DFI4_PROMOTE_THRESHOLD_F1 — Defines the DFI(4.0 and 4.0v2) PHY master request promotion number of regular (not long) counts until the high priority request is asserted for frequency copy 1.
0x1CC DDRSS_CTL_115
  [19:0] TDFI_PHYMSTR_RESP_F1 — Defines the DFI tPHYMSTR_RESP timing parameter (in DFI clocks), the maximum cycles between a dfi_phymstr_req assertion and a dfi_phymstr_ack assertion, for frequency copy 1.
0x1D0 DDRSS_CTL_116
  [31:0] TDFI_PHYMSTR_MAX_F2 — Defines the DFI tPHYMSTR_MAX timing parameter (in DFI clocks), the maximum cycles that dfi_phymstr_req can be asserted following the assertion of dfi_phymstr_ack, for frequency copy 2.
{0x0+4i} DDRSS_CTL_{i} (i=117..120)
  [31:0] TDFI_PHYMSTR_MAX_TYPE{i-117}_F2 — Defines the DFI 4.0v2 tPHYMSTR_MAX_TYPE{i-117} timing parameter (in DFI clocks), the maximum cycles that dfi_phymstr_req can be asserted following the assertion of dfi_phymstr_ack for dfi_phymstr_type={i-117}, for frequency copy 2.
0x1E4 DDRSS_CTL_121
  [15:0] PHYMSTR_DFI4_PROMOTE_THRESHOLD_F2 — Defines the DFI(4.0 and 4.0v2) PHY master request promotion number of regular (not long) counts until the high priority request is asserted for frequency copy 2.
0x1E8 DDRSS_CTL_122
  [24] PHYMSTR_NO_AREF — Disables refreshes during the PHY master interface sequence.
  [19:0] TDFI_PHYMSTR_RESP_F2 — Defines the DFI tPHYMSTR_RESP timing parameter (in DFI clocks), the maximum cycles between a dfi_phymstr_req assertion and a dfi_phymstr_ack assertion, for frequency copy 2.
0x1EC DDRSS_CTL_123 access per field
  [16] PHYMSTR_TRAIN_AFTER_INIT_COMPLETE rw — Defines how the PHY will use the PHY Master Interface for training.
  [8] PHYMSTR_DFI_VERSION_4P0V1 rw — Defines the version of the DFI 4.0 specification supported.
  [1:0] PHYMSTR_ERROR_STATUS ro — Identifies the source of any DFI PHY Master Interface errors.
0x1F0 DDRSS_CTL_124
  [31:16] MRR_TEMPCHK_HIGH_THRESHOLD_F0 — MRR temp check number of long counts until the high priority request is asserted for frequency copy 0.
  [15:0] MRR_TEMPCHK_NORM_THRESHOLD_F0 — MRR temp check number of long counts until the normal priority request is asserted for frequency copy 0.
0x1F4 DDRSS_CTL_125
  [31:16] MRR_TEMPCHK_NORM_THRESHOLD_F1 — MRR temp check number of long counts until the normal priority request is asserted for frequency copy 1.
  [15:0] MRR_TEMPCHK_TIMEOUT_F0 — MRR temp check number of long counts until the timeout is asserted for frequency copy 0.
0x1F8 DDRSS_CTL_126
  [31:16] MRR_TEMPCHK_TIMEOUT_F1 — MRR temp check number of long counts until the timeout is asserted for frequency copy 1.
  [15:0] MRR_TEMPCHK_HIGH_THRESHOLD_F1 — MRR temp check number of long counts until the high priority request is asserted for frequency copy 1.
0x1FC DDRSS_CTL_127
  [31:16] MRR_TEMPCHK_HIGH_THRESHOLD_F2 — MRR temp check number of long counts until the high priority request is asserted for frequency copy 2.
  [15:0] MRR_TEMPCHK_NORM_THRESHOLD_F2 — MRR temp check number of long counts until the normal priority request is asserted for frequency copy 2.
0x200 DDRSS_CTL_128 access per field
  [26:24] PPR_COMMAND wo — Specifies the type of PPR command.
  [16] PPR_CONTROL rw — Enables the post-package repair feature.
  [15:0] MRR_TEMPCHK_TIMEOUT_F2 rw — MRR temp check number of long counts until the timeout is asserted for frequency copy 2.
0x204 DDRSS_CTL_129
  [24:8] PPR_ROW_ADDRESS — Specifies the encoded row address to be repaired.
  [7:0] PPR_COMMAND_MRW — Specifies the mode register to be used.
0x208 DDRSS_CTL_130 access per field
  [24] FM_OVRIDE_CONTROL rw — Enables the FM Override feature.
  [17:16] PPR_STATUS ro — Reports the status of the PPR operation.
  [8] PPR_CS_ADDRESS rw — Specifies the chip select for the row to be repaired.
  [2:0] PPR_BANK_ADDRESS rw — Specifies the bank for the row to be repaired.
0x20C DDRSS_CTL_131
  [31:24] CKSRE_F1 — Clock hold delay on self-refresh entry for frequency copy 1.
  [23:16] CKSRX_F0 — Clock stable delay on self-refresh exit for frequency copy 0.
  [15:8] CKSRE_F0 — Clock hold delay on self-refresh entry for frequency copy 0.
  [1:0] LOWPOWER_REFRESH_ENABLE — Enable refreshes while in low power mode.
0x210 DDRSS_CTL_132 access per field
  [30:24] LP_CMD wo — Low power software command request interface.
  [23:16] CKSRX_F2 rw — Clock stable delay on self-refresh exit for frequency copy 2.
  [15:8] CKSRE_F2 rw — Clock hold delay on self-refresh entry for frequency copy 2.
  [7:0] CKSRX_F1 rw — Clock stable delay on self-refresh exit for frequency copy 1.
0x214 DDRSS_CTL_133
  [27:24] LPI_SR_LONG_MCCLK_GATE_WAKEUP_F0 — Defines the DFI tLP_WAKEUP timing parameter (in DFI clocks) to be driven when memory is in the self-refresh long with memory and controller clock gating state, for frequency copy 0.
  [19:16] LPI_SR_LONG_WAKEUP_F0 — Defines the DFI tLP_WAKEUP timing parameter (in DFI clocks) to be driven when memory is in the self-refresh long state (with or without memory clock gating) for frequency copy 0.
  [11:8] LPI_SR_SHORT_WAKEUP_F0 — Defines the DFI tLP_WAKEUP timing parameter (in DFI clocks) to be driven when LPDDR4 memory is in the self-refresh short state (with or without memory clock gating) for frequency copy 0.
  [3:0] LPI_CTRL_IDLE_WAKEUP_F0 — Defines the DFI tLP_WAKEUP timing parameter (in DFI clocks) to be driven when controller is idle for frequency copy 0.
0x218 DDRSS_CTL_134
  [27:24] LPI_SRPD_LONG_MCCLK_GATE_WAKEUP_F0 — Defines the DFI tLP_WAKEUP timing parameter (in DFI clocks) to be driven when memory is in the self-refresh power-down long with memory and controller clock gating state, for frequency copy 0.
  [19:16] LPI_SRPD_LONG_WAKEUP_F0 — Defines the DFI tLP_WAKEUP timing parameter (in DFI clocks) to be driven when memory is in the self-refresh power-down long state (with or without memory clock gating), for frequency copy 0.
  [11:8] LPI_SRPD_SHORT_WAKEUP_F0 — Defines the DFI tLP_WAKEUP timing parameter (in DFI clocks) to be driven when memory is in the self-refresh power-down short state (with or without memory clock gating), for frequency copy 0.
  [3:0] LPI_PD_WAKEUP_F0 — Defines the DFI tLP_WAKEUP timing parameter (in DFI clocks) to be driven when memory is in any of the power-down states (with or without memory clock gating) for frequency copy 0.
0x21C DDRSS_CTL_135
  [27:24] LPI_SR_LONG_WAKEUP_F1 — Defines the DFI tLP_WAKEUP timing parameter (in DFI clocks) to be driven when memory is in the self-refresh long state (with or without memory clock gating) for frequency copy 1.
  [19:16] LPI_SR_SHORT_WAKEUP_F1 — Defines the DFI tLP_WAKEUP timing parameter (in DFI clocks) to be driven when LPDDR4 memory is in the self-refresh short state (with or without memory clock gating) for frequency copy 1.
  [11:8] LPI_CTRL_IDLE_WAKEUP_F1 — Defines the DFI tLP_WAKEUP timing parameter (in DFI clocks) to be driven when controller is idle for frequency copy 1.
  [3:0] LPI_TIMER_WAKEUP_F0 — Defines the DFI tLP_WAKEUP timing parameter (in DFI clocks) to be driven when the LPI timer expires for frequency copy 0.
0x220 DDRSS_CTL_136
  [27:24] LPI_SRPD_LONG_WAKEUP_F1 — Defines the DFI tLP_WAKEUP timing parameter (in DFI clocks) to be driven when memory is in the self-refresh power-down long state (with or without memory clock gating), for frequency copy 1.
  [19:16] LPI_SRPD_SHORT_WAKEUP_F1 — Defines the DFI tLP_WAKEUP timing parameter (in DFI clocks) to be driven when memory is in the self-refresh power-down short state (with or without memory clock gating), for frequency copy 1.
  [11:8] LPI_PD_WAKEUP_F1 — Defines the DFI tLP_WAKEUP timing parameter (in DFI clocks) to be driven when memory is in any of the power-down states (with or without memory clock gating) for frequency copy 1.
  [3:0] LPI_SR_LONG_MCCLK_GATE_WAKEUP_F1 — Defines the DFI tLP_WAKEUP timing parameter (in DFI clocks) to be driven when memory is in the self-refresh long with memory and controller clock gating state, for frequency copy 1.
0x224 DDRSS_CTL_137
  [27:24] LPI_SR_SHORT_WAKEUP_F2 — Defines the DFI tLP_WAKEUP timing parameter (in DFI clocks) to be driven when LPDDR4 memory is in the self-refresh short state (with or without memory clock gating) for frequency copy 2.
  [19:16] LPI_CTRL_IDLE_WAKEUP_F2 — Defines the DFI tLP_WAKEUP timing parameter (in DFI clocks) to be driven when controller is idle for frequency copy 2.
  [11:8] LPI_TIMER_WAKEUP_F1 — Defines the DFI tLP_WAKEUP timing parameter (in DFI clocks) to be driven when the LPI timer expires for frequency copy 1.
  [3:0] LPI_SRPD_LONG_MCCLK_GATE_WAKEUP_F1 — Defines the DFI tLP_WAKEUP timing parameter (in DFI clocks) to be driven when memory is in the self-refresh power-down long with memory and controller clock gating state, for frequency copy 1.
0x228 DDRSS_CTL_138
  [27:24] LPI_SRPD_SHORT_WAKEUP_F2 — Defines the DFI tLP_WAKEUP timing parameter (in DFI clocks) to be driven when memory is in the self-refresh power-down short state (with or without memory clock gating), for frequency copy 2.
  [19:16] LPI_PD_WAKEUP_F2 — Defines the DFI tLP_WAKEUP timing parameter (in DFI clocks) to be driven when memory is in any of the power-down states (with or without memory clock gating) for frequency copy 2.
  [11:8] LPI_SR_LONG_MCCLK_GATE_WAKEUP_F2 — Defines the DFI tLP_WAKEUP timing parameter (in DFI clocks) to be driven when memory is in the self-refresh long with memory and controller clock gating state, for frequency copy 2.
  [3:0] LPI_SR_LONG_WAKEUP_F2 — Defines the DFI tLP_WAKEUP timing parameter (in DFI clocks) to be driven when memory is in the self-refresh long state (with or without memory clock gating) for frequency copy 2.
0x22C DDRSS_CTL_139
  [29:24] LPI_WAKEUP_EN — Enables the various low power state wakeup parameters for LPI request uses.
  [19:16] LPI_TIMER_WAKEUP_F2 — Defines the DFI tLP_WAKEUP timing parameter (in DFI clocks) to be driven when the LPI timer expires for frequency copy 2.
  [11:8] LPI_SRPD_LONG_MCCLK_GATE_WAKEUP_F2 — Defines the DFI tLP_WAKEUP timing parameter (in DFI clocks) to be driven when memory is in the self-refresh power-down long with memory and controller clock gating state, for frequency copy 2.
  [3:0] LPI_SRPD_LONG_WAKEUP_F2 — Defines the DFI tLP_WAKEUP timing parameter (in DFI clocks) to be driven when memory is in the self-refresh power-down long state (with or without memory clock gating), for frequency copy 2.
0x230 DDRSS_CTL_140
  [26:24] TDFI_LP_RESP — Defines the DFI tLP_RESP timing parameter (in DFI clocks), the maximum cycles between a dfi_lp_req assertion and a dfi_lp_ack assertion.
  [19:8] LPI_WAKEUP_TIMEOUT — Defines the LPI timeout time, the maximum cycles between a dfi_lp_req de-assertion and a dfi_lp_ack de-assertion.
  [0] LPI_CTRL_REQ_EN — Enables the dfi_lpi_ctrl_req signal for the LPI.
0x234 DDRSS_CTL_141 access per field reset 0x4040
  [27:24] LP_AUTO_EXIT_EN rw — Enable auto exit from each of the low power states when a read or write command enters the command queue.
  [19:16] LP_AUTO_ENTRY_EN rw — Enable auto entry into each of the low power states when the associated idle timer expires.
  [14:8] LP_STATE_CS1 ro — Low power state status parameter for chip select 1.
  [6:0] LP_STATE_CS0 ro — Low power state status parameter for chip select 0.
0x238 DDRSS_CTL_142
  [19:8] LP_AUTO_PD_IDLE — Defines the idle time (in controller clocks) until the controller will automatically issue an entry into one of the power-down low power states.
  [2:0] LP_AUTO_MEM_GATE_EN — Enable memory clock gating when entering a low power state via the auto low power counters.
0x23C DDRSS_CTL_143
  [31:24] LP_AUTO_SR_LONG_MC_GATE_IDLE — Defines the idle time (in long counts) until the controller will automatically issue an entry into the self-refresh long with memory and controller clock gating or self-refresh power-down long with memory and controller clock gating low power states.
  [23:16] LP_AUTO_SR_LONG_IDLE — Defines the idle time (in long counts) until the controller will automatically issue an entry into the self-refresh long or self-refresh power-down long (with or without memory clock gating) low power states.
  [11:0] LP_AUTO_SR_SHORT_IDLE — Defines the idle time (in controller clocks) until the controller will automatically issue an entry into the self-refresh short or self-refresh power-down short (with or without memory clock gating) low power states.
0x240 DDRSS_CTL_144
  [31:16] HW_PROMOTE_THRESHOLD_F1 — HW interface promotion number of long counts until the high priority request is asserted for frequency copy 1.
  [15:0] HW_PROMOTE_THRESHOLD_F0 — HW interface promotion number of long counts until the high priority request is asserted for frequency copy 0.
0x244 DDRSS_CTL_145
  [31:16] LPC_PROMOTE_THRESHOLD_F0 — LPC promotion number of long counts until the high priority request is asserted for frequency copy 0.
  [15:0] HW_PROMOTE_THRESHOLD_F2 — HW interface promotion number of long counts until the high priority request is asserted for frequency copy 2.
0x248 DDRSS_CTL_146
  [31:16] LPC_PROMOTE_THRESHOLD_F2 — LPC promotion number of long counts until the high priority request is asserted for frequency copy 2.
  [15:0] LPC_PROMOTE_THRESHOLD_F1 — LPC promotion number of long counts until the high priority request is asserted for frequency copy 1.
